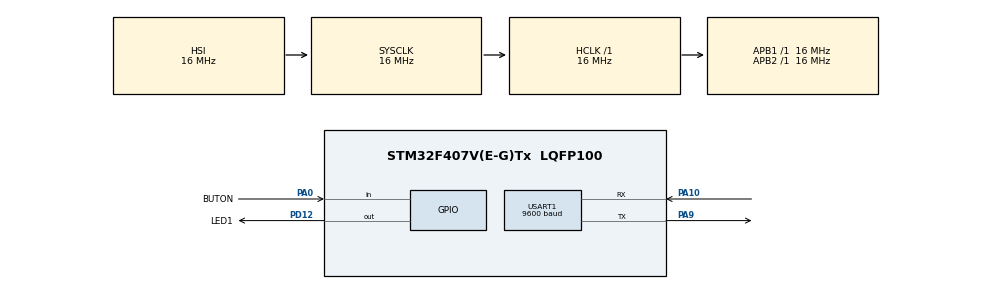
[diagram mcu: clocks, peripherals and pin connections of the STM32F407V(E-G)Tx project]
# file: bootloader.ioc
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Mcu.Family=STM32F4
Mcu.Name=STM32F407V(E-G)Tx
Mcu.Package=LQFP100
NVIC.PriorityGroup=NVIC_PRIORITYGROUP_4
PA0-WKUP.GPIO_Label=BUTON
PA0-WKUP.Signal=GPIO_Input
PA10.Mode=Asynchronous
PA10.Signal=USART1_RX
PA9.Mode=Asynchronous
PA9.Signal=USART1_TX
PD12.GPIO_Label=LED1
PD12.GPIO_Speed=GPIO_SPEED_FREQ_MEDIUM
PD12.Signal=GPIO_Output
ProjectManager.HeapSize=0x200
ProjectManager.StackSize=0x400
ProjectManager.TargetToolchain=STM32CubeIDE
RCC.AHBFreq_Value=16000000
RCC.APB1Freq_Value=16000000
RCC.APB2Freq_Value=16000000
RCC.CortexFreq_Value=16000000
RCC.HSE_VALUE=25000000
RCC.HSI_VALUE=16000000
RCC.LSE_VALUE=32768
RCC.SYSCLKFreq_VALUE=16000000
RCC.VCOOutputFreq_Value=192000000
USART1.BaudRate=9600
USART1.VirtualMode=VM_ASYNC
board=custom

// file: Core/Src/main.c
/* USER CODE BEGIN Header */
/**
  ******************************************************************************
  * @file           : main.c
  * @brief          : Main program body
  ******************************************************************************
  * @attention
  *
  * Copyright (c) 2025 STMicroelectronics.
  * All rights reserved.
  *
  * This software is licensed under terms that can be found in the LICENSE file
  * in the root directory of this software component.
  * If no LICENSE file comes with this software, it is provided AS-IS.
  *
  ******************************************************************************
  */
/* USER CODE END Header */
#include "main.h"

/* USER CODE BEGIN Includes */
#include <string.h>
#include <jump_bootloader.h>
#include <stdlib.h>
/* USER CODE END Includes */

/* USER CODE BEGIN PD */
//typedef void (*pFunction)(void);
//#define APP_ADDRESS  0x08008000  // User_app flash adresi
/* USER CODE END PD */

UART_HandleTypeDef huart1;

/* USER CODE BEGIN PV */
char rxMessage[3];
int receivedData =0;
/* USER CODE END PV */

void SystemClock_Config(void);
static void MX_GPIO_Init(void);
static void MX_USART1_UART_Init(void);

/* USER CODE BEGIN 0 */

//void Jump_To_Application(void) {
//    uint32_t JumpAddress;
//    pFunction Jump_To_App;
//
//    // User_APP stack pointer adresini al
//    uint32_t app_stack_pointer = *(volatile uint32_t*)APP_ADDRESS;
//
//    // Eğer uygulama yüklü değilse çık
//    if (app_stack_pointer < 0x20000000 || app_stack_pointer > 0x2004FFFF) {
//        return;
//    }
//
//    // Uygulamanın reset vektörünü al
//    JumpAddress = *(volatile uint32_t*) (APP_ADDRESS + 4);
//    Jump_To_App = (pFunction) JumpAddress;
//
//    // Kesme vektör tablosu başlangıç adresini güncelle
//    SCB->VTOR = APP_ADDRESS;
//
//    // Stack pointer'ı uygula
//    __set_MSP(app_stack_pointer);
//
//    // Uygulamaya atla
//    Jump_To_App();
//}

/* USER CODE END 0 */

int main(void)
{

  /* MCU Configuration--------------------------------------------------------*/

  /* Reset of all peripherals, Initializes the Flash interface and the Systick. */
  HAL_Init();

  /* Configure the system clock */
  SystemClock_Config();

  /* Initialize all configured peripherals */
  MX_GPIO_Init();
  MX_USART1_UART_Init();

  /* Infinite loop */
  while (1)
  {

    /* USER CODE BEGIN 3 */

	  /*BUTON İLE ATLAMA*/

//	  if (HAL_GPIO_ReadPin(BUTON_GPIO_Port,BUTON_Pin) == GPIO_PIN_SET) {
//		  Jump_To_Application();
//	  }

	  /*USART İLE ATLAMA*/

	  memset(rxMessage, 0, sizeof(rxMessage));	/* buffer temizleme her yeni veride*/

	    if (HAL_UART_Receive(&huart1, (uint8_t *)rxMessage, sizeof(rxMessage), HAL_MAX_DELAY) == HAL_OK) {

	        //rxMessage[strcspn(rxMessage, "\r\n")] = 0; /* boş karakter temizleme*/
	        receivedData = atoi(rxMessage); // string->int yaptık

	        if (receivedData == 42) {
	            Jump_To_Application();
	        }
//KENDİMİ ASMADAN ÖNCEKİ SON DENEMELER T�?K
	    }

  }
  /* USER CODE END 3 */
}

void SystemClock_Config(void)
{
  RCC_OscInitTypeDef RCC_OscInitStruct = {0};
  RCC_ClkInitTypeDef RCC_ClkInitStruct = {0};

  /** Configure the main internal regulator output voltage
  */
  __HAL_RCC_PWR_CLK_ENABLE();
  __HAL_PWR_VOLTAGESCALING_CONFIG(PWR_REGULATOR_VOLTAGE_SCALE1);

  /** Initializes the RCC Oscillators according to the specified parameters
  * in the RCC_OscInitTypeDef structure.
  */
  RCC_OscInitStruct.OscillatorType = RCC_OSCILLATORTYPE_HSI;
  RCC_OscInitStruct.HSIState = RCC_HSI_ON;
  RCC_OscInitStruct.HSICalibrationValue = RCC_HSICALIBRATION_DEFAULT;
  RCC_OscInitStruct.PLL.PLLState = RCC_PLL_NONE;
  if (HAL_RCC_OscConfig(&RCC_OscInitStruct) != HAL_OK)
  {
    Error_Handler();
  }

  /** Initializes the CPU, AHB and APB buses clocks
  */
  RCC_ClkInitStruct.ClockType = RCC_CLOCKTYPE_HCLK|RCC_CLOCKTYPE_SYSCLK
                              |RCC_CLOCKTYPE_PCLK1|RCC_CLOCKTYPE_PCLK2;
  RCC_ClkInitStruct.SYSCLKSource = RCC_SYSCLKSOURCE_HSI;
  RCC_ClkInitStruct.AHBCLKDivider = RCC_SYSCLK_DIV1;
  RCC_ClkInitStruct.APB1CLKDivider = RCC_HCLK_DIV1;
  RCC_ClkInitStruct.APB2CLKDivider = RCC_HCLK_DIV1;

  if (HAL_RCC_ClockConfig(&RCC_ClkInitStruct, FLASH_LATENCY_0) != HAL_OK)
  {
    Error_Handler();
  }
}

static void MX_USART1_UART_Init(void)
{

  huart1.Instance = USART1;
  huart1.Init.BaudRate = 9600;
  huart1.Init.WordLength = UART_WORDLENGTH_8B;
  huart1.Init.StopBits = UART_STOPBITS_1;
  huart1.Init.Parity = UART_PARITY_NONE;
  huart1.Init.Mode = UART_MODE_TX_RX;
  huart1.Init.HwFlowCtl = UART_HWCONTROL_NONE;
  huart1.Init.OverSampling = UART_OVERSAMPLING_16;
  if (HAL_UART_Init(&huart1) != HAL_OK)
  {
    Error_Handler();
  }

}

static void MX_GPIO_Init(void)
{
  GPIO_InitTypeDef GPIO_InitStruct = {0};

  /* GPIO Ports Clock Enable */
  __HAL_RCC_GPIOA_CLK_ENABLE();
  __HAL_RCC_GPIOD_CLK_ENABLE();

  /*Configure GPIO pin Output Level */
  HAL_GPIO_WritePin(LED1_GPIO_Port, LED1_Pin, GPIO_PIN_RESET);

  /*Configure GPIO pin : BUTON_Pin */
  GPIO_InitStruct.Pin = BUTON_Pin;
  GPIO_InitStruct.Mode = GPIO_MODE_INPUT;
  GPIO_InitStruct.Pull = GPIO_NOPULL;
  HAL_GPIO_Init(BUTON_GPIO_Port, &GPIO_InitStruct);

  /*Configure GPIO pin : LED1_Pin */
  GPIO_InitStruct.Pin = LED1_Pin;
  GPIO_InitStruct.Mode = GPIO_MODE_OUTPUT_PP;
  GPIO_InitStruct.Pull = GPIO_NOPULL;
  GPIO_InitStruct.Speed = GPIO_SPEED_FREQ_MEDIUM;
  HAL_GPIO_Init(LED1_GPIO_Port, &GPIO_InitStruct);

}

void Error_Handler(void)
{
  __disable_irq();
  while (1)
  {
  }
}
